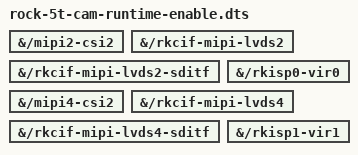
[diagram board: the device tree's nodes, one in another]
/dts-v1/;
/plugin/;

/*
 * Runtime enable of the ROCK 5T camera pipeline (dual IMX477) — PHASE 1.
 *
 * Applied AFTER boot by rk_cam_defer_enable.ko (../driver/), once the
 * out-of-tree imx477 sensor driver has loaded and async-registered both
 * sensors. The boot overlay (rock-5t-dual-rpi-hq-imx477.dts) deliberately
 * leaves these nodes disabled so the vendor kernel's late_initcall
 * "clear unready subdev" pass (which would permanently orphan a
 * not-yet-registered sensor) has nothing camera-related to clear.
 *
 * TWO-PHASE ENABLE (both required, in order):
 *   phase 1 (this file): csi2 receivers + CIF + sditf + ISP vir devices.
 *     The chain assembles but cannot complete — each mipi-csi2's own
 *     notifier still waits for its (still-disabled) D-PHY — which keeps
 *     rkcif's one-shot "notifier isp" thread parked while the sditf
 *     bridges attach to their CIF devices (the vendor thread silently
 *     skips sditf-to-ISP registration if it wakes before the sditf has
 *     attached, with no retry — a ms-scale race a single-overlay apply
 *     loses).
 *   phase 2 (rock-5t-cam-runtime-enable-p2.dts): the two D-PHYs. Their
 *     probe matches the already-registered sensors and the completion
 *     cascade runs bottom-up with everything in place.
 *
 * Pure target-path + status fragments: build with plain dtc (no -@):
 *
 *   dtc -I dts -O dtb -o rock5t-cam-enable-p1.dtbo rock-5t-cam-runtime-enable.dts
 *   dtc -I dts -O dtb -o rock5t-cam-enable-p2.dtbo rock-5t-cam-runtime-enable-p2.dts
 *   sudo cp rock5t-cam-enable-p1.dtbo rock5t-cam-enable-p2.dtbo /lib/firmware/
 */

/ {
	fragment@0 {
		target-path = "/mipi2-csi2";
		__overlay__ { status = "okay"; };
	};

	fragment@1 {
		target-path = "/rkcif-mipi-lvds2";
		__overlay__ { status = "okay"; };
	};

	fragment@2 {
		target-path = "/rkcif-mipi-lvds2-sditf";
		__overlay__ { status = "okay"; };
	};

	fragment@3 {
		target-path = "/rkisp0-vir0";
		__overlay__ { status = "okay"; };
	};

	fragment@4 {
		target-path = "/mipi4-csi2";
		__overlay__ { status = "okay"; };
	};

	fragment@5 {
		target-path = "/rkcif-mipi-lvds4";
		__overlay__ { status = "okay"; };
	};

	fragment@6 {
		target-path = "/rkcif-mipi-lvds4-sditf";
		__overlay__ { status = "okay"; };
	};

	fragment@7 {
		target-path = "/rkisp1-vir1";
		__overlay__ { status = "okay"; };
	};
};
